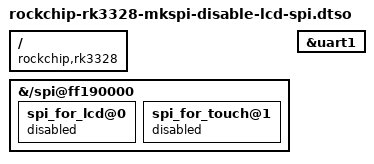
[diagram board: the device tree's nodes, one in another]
/dts-v1/;
/plugin/;

/ {
	compatible = "rockchip,rk3328";
};

&{/spi@ff190000} {
	spi_for_lcd@0 {
		status = "disabled";
	};
	spi_for_touch@1 {
		status = "disabled";
	};
};

&uart1 {
	status = "okay";
};
